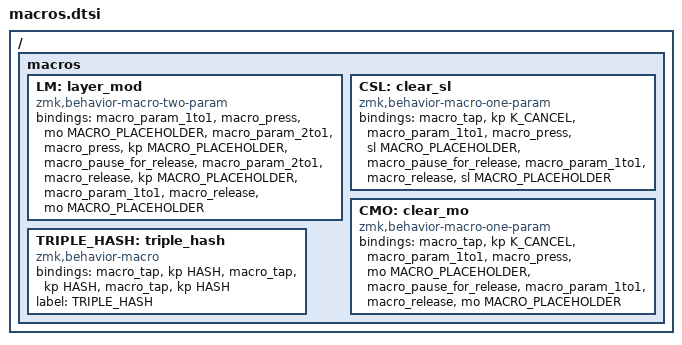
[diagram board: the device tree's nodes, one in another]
/ {
  macros {

    /* ───────────  Short-layer/clear helpers supplied by ZMK  ─────────── */
    LM: layer_mod    { compatible = "zmk,behavior-macro-two-param"; #binding-cells = <2>;
                       bindings = <&macro_param_1to1>, <&macro_press &mo MACRO_PLACEHOLDER>,
                                  <&macro_param_2to1>, <&macro_press &kp MACRO_PLACEHOLDER>,
                                  <&macro_pause_for_release>,
                                  <&macro_param_2to1>, <&macro_release &kp MACRO_PLACEHOLDER>,
                                  <&macro_param_1to1>, <&macro_release &mo MACRO_PLACEHOLDER>; };

    CSL: clear_sl    { compatible = "zmk,behavior-macro-one-param";  #binding-cells = <1>;
                       bindings = <&macro_tap &kp K_CANCEL>, <&macro_param_1to1>,
                                  <&macro_press &sl MACRO_PLACEHOLDER>,
                                  <&macro_pause_for_release>,
                                  <&macro_param_1to1>, <&macro_release &sl MACRO_PLACEHOLDER>; };

    CMO: clear_mo    { compatible = "zmk,behavior-macro-one-param";  #binding-cells = <1>;
                       bindings = <&macro_tap &kp K_CANCEL>, <&macro_param_1to1>,
                                  <&macro_press &mo MACRO_PLACEHOLDER>,
                                  <&macro_pause_for_release>,
                                  <&macro_param_1to1>, <&macro_release &mo MACRO_PLACEHOLDER>; };


    TRIPLE_HASH: triple_hash {
      compatible = "zmk,behavior-macro";
      #binding-cells = <0>;
      bindings = 
        <&macro_tap &kp HASH>,
        <&macro_tap &kp HASH>,
        <&macro_tap &kp HASH>;
      label = "TRIPLE_HASH";
    };

    /* ───────────  Simplified macros for 2-layer design  ─────────── */
    
    // Keep basic macros if needed in the future
    // Most functionality will be handled by Hyprland + Super key combinations
  };
};
